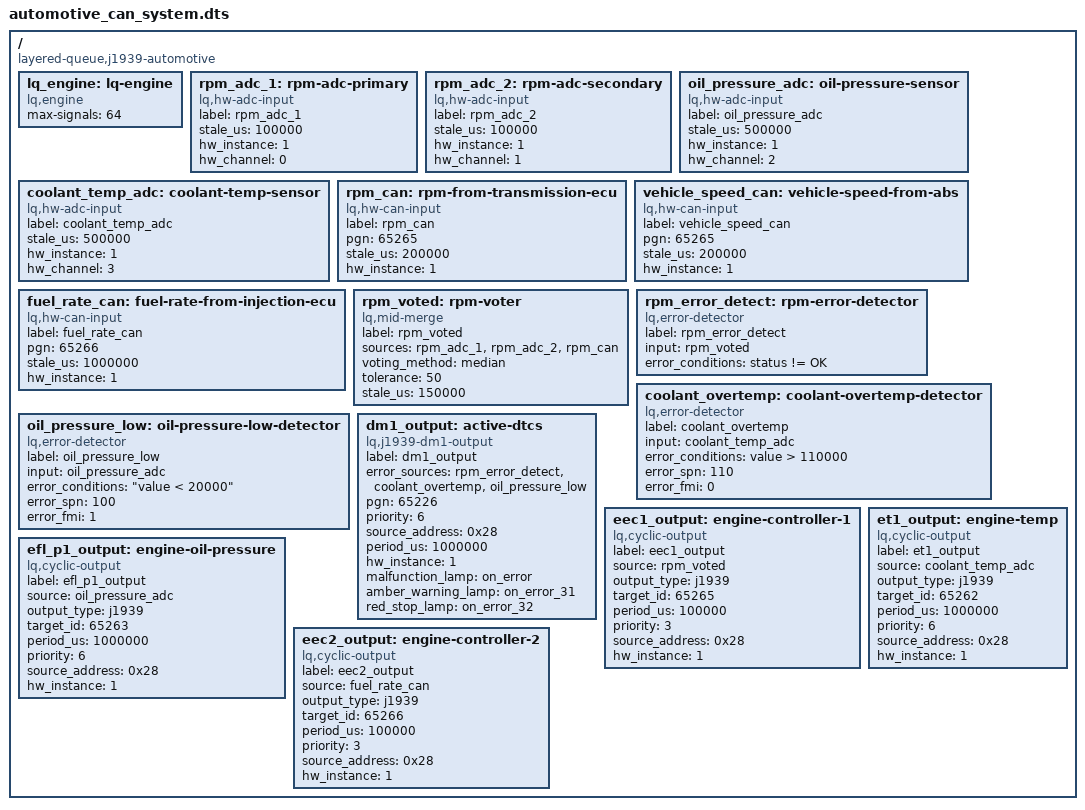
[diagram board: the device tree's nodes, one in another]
/*
 * Complete J1939 Automotive System with CAN
 * 
 * This example demonstrates:
 * - CAN input (receiving J1939 messages from other ECUs)
 * - CAN output (transmitting J1939 PGNs)
 * - J1939 DM1 diagnostic messages on errors
 * - Triple-redundant sensor voting
 * - Error detection and fault reporting
 */

/ {
    compatible = "layered-queue,j1939-automotive";
    
    lq_engine: lq-engine {
        compatible = "lq,engine";
        max-signals = <64>;
    };
    
    /* ========================================
     * HARDWARE INPUTS
     * ======================================== */
    
    /* Local ADC sensors */
    rpm_adc_1: rpm-adc-primary {
        compatible = "lq,hw-adc-input";
        label = "rpm_adc_1";
        stale_us = <100000>;  /* 100ms */
        hw_instance = <1>;
        hw_channel = <0>;
    };
    
    rpm_adc_2: rpm-adc-secondary {
        compatible = "lq,hw-adc-input";
        label = "rpm_adc_2";
        stale_us = <100000>;
        hw_instance = <1>;
        hw_channel = <1>;
    };
    
    oil_pressure_adc: oil-pressure-sensor {
        compatible = "lq,hw-adc-input";
        label = "oil_pressure_adc";
        stale_us = <500000>;
        hw_instance = <1>;
        hw_channel = <2>;
    };
    
    coolant_temp_adc: coolant-temp-sensor {
        compatible = "lq,hw-adc-input";
        label = "coolant_temp_adc";
        stale_us = <500000>;
        hw_instance = <1>;
        hw_channel = <3>;
    };
    
    /* CAN inputs from other ECUs */
    rpm_can: rpm-from-transmission-ecu {
        compatible = "lq,hw-can-input";
        label = "rpm_can";
        pgn = <65265>;  /* J1939 EEC1 - Electronic Engine Controller 1 */
        stale_us = <200000>;
        hw_instance = <1>;
    };
    
    vehicle_speed_can: vehicle-speed-from-abs {
        compatible = "lq,hw-can-input";
        label = "vehicle_speed_can";
        pgn = <65265>;  /* J1939 EEC1 contains vehicle speed */
        stale_us = <200000>;
        hw_instance = <1>;
    };
    
    fuel_rate_can: fuel-rate-from-injection-ecu {
        compatible = "lq,hw-can-input";
        label = "fuel_rate_can";
        pgn = <65266>;  /* J1939 EEC2 - Electronic Engine Controller 2 */
        stale_us = <1000000>;
        hw_instance = <1>;
    };
    
    /* ========================================
     * MERGE/VOTING LAYER
     * ======================================== */
    
    /* Triple-redundant RPM voting */
    rpm_voted: rpm-voter {
        compatible = "lq,mid-merge";
        label = "rpm_voted";
        sources = <&rpm_adc_1 &rpm_adc_2 &rpm_can>;
        voting_method = "median";
        tolerance = <50>;  /* 50 RPM tolerance */
        stale_us = <150000>;
    };
    
    /* ========================================
     * ERROR DETECTION
     * ======================================== */
    
    /* Detect RPM sensor disagreement */
    rpm_error_detect: rpm-error-detector {
        compatible = "lq,error-detector";
        label = "rpm_error_detect";
        input = <&rpm_voted>;
        
        /* Trigger error if voted value is INCONSISTENT */
        error_conditions = "status != OK";
    };
    
    /* Detect high coolant temperature */
    coolant_overtemp: coolant-overtemp-detector {
        compatible = "lq,error-detector";
        label = "coolant_overtemp";
        input = <&coolant_temp_adc>;
        
        /* Trigger if temp > 110°C (adjustable threshold) */
        error_conditions = "value > 110000";
        error_spn = <110>;  /* J1939 SPN for coolant temp */
        error_fmi = <0>;    /* FMI 0: Data above normal */
    };
    
    /* Detect low oil pressure */
    oil_pressure_low: oil-pressure-low-detector {
        compatible = "lq,error-detector";
        label = "oil_pressure_low";
        input = <&oil_pressure_adc>;
        
        /* Trigger if pressure < 20 kPa */
        error_conditions = "value < 20000";
        error_spn = <100>;  /* J1939 SPN for oil pressure */
        error_fmi = <1>;    /* FMI 1: Data below normal */
    };
    
    /* ========================================
     * J1939 DIAGNOSTIC OUTPUT (DM1)
     * ======================================== */
    
    dm1_output: active-dtcs {
        compatible = "lq,j1939-dm1-output";
        label = "dm1_output";
        
        /* Monitor these error signals */
        error_sources = <&rpm_error_detect &coolant_overtemp &oil_pressure_low>;
        
        /* DM1 message configuration */
        pgn = <65226>;  /* J1939 DM1 PGN */
        priority = <6>;
        source_address = <0x28>;  /* Engine #1 */
        
        /* Send DM1 when errors active, stop when cleared */
        period_us = <1000000>;  /* 1Hz when active */
        hw_instance = <1>;
        
        /* Lamp control */
        malfunction_lamp = "on_error";      /* MIL on for any error */
        amber_warning_lamp = "on_error_31"; /* Amber for coolant temp */
        red_stop_lamp = "on_error_32";      /* Red for low oil pressure */
    };
    
    /* ========================================
     * CYCLIC J1939 OUTPUTS
     * ======================================== */
    
    /* EEC1 - Engine Controller (contains RPM) */
    eec1_output: engine-controller-1 {
        compatible = "lq,cyclic-output";
        label = "eec1_output";
        source = <&rpm_voted>;
        output_type = "j1939";
        target_id = <65265>;  /* PGN 0xFEF1 - EEC1 */
        period_us = <100000>; /* 10Hz (100ms) */
        priority = <3>;
        source_address = <0x28>;
        hw_instance = <1>;
    };
    
    /* ET1 - Engine Temperature */
    et1_output: engine-temp {
        compatible = "lq,cyclic-output";
        label = "et1_output";
        source = <&coolant_temp_adc>;
        output_type = "j1939";
        target_id = <65262>;  /* PGN 0xFEEE - ET1 */
        period_us = <1000000>; /* 1Hz (1s) */
        priority = <6>;
        source_address = <0x28>;
        hw_instance = <1>;
    };
    
    /* EFL/P1 - Engine Fluid Level/Pressure */
    efl_p1_output: engine-oil-pressure {
        compatible = "lq,cyclic-output";
        label = "efl_p1_output";
        source = <&oil_pressure_adc>;
        output_type = "j1939";
        target_id = <65263>;  /* PGN 0xFEEF - EFL/P1 */
        period_us = <1000000>; /* 1Hz (1s) */
        priority = <6>;
        source_address = <0x28>;
        hw_instance = <1>;
    };
    
    /* EEC2 - Engine Controller 2 (fuel rate from CAN input) */
    eec2_output: engine-controller-2 {
        compatible = "lq,cyclic-output";
        label = "eec2_output";
        source = <&fuel_rate_can>;
        output_type = "j1939";
        target_id = <65266>;  /* PGN 0xFEF2 - EEC2 */
        period_us = <100000>; /* 10Hz (100ms) */
        priority = <3>;
        source_address = <0x28>;
        hw_instance = <1>;
    };
};
